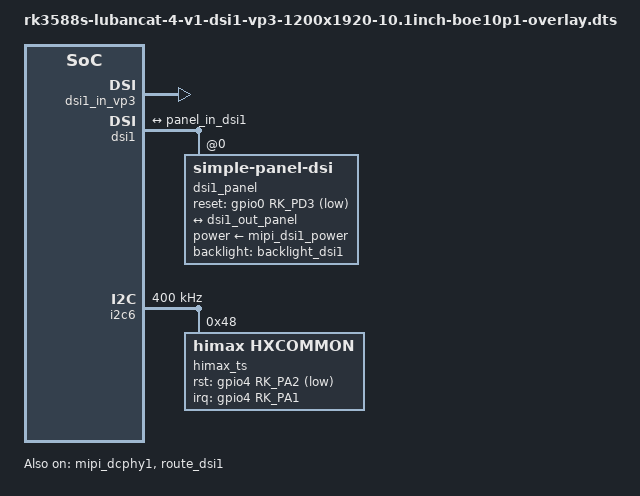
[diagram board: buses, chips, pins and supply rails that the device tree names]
/dts-v1/;
/plugin/;

#include <dt-bindings/gpio/gpio.h>
#include <dt-bindings/pinctrl/rockchip.h>
#include <dt-bindings/display/drm_mipi_dsi.h>
#include <dt-bindings/interrupt-controller/irq.h>

/ {
	fragment@0 {
		target = <&mipi_dcphy1>;

		__overlay__ {
			status = "okay";
		};
	};

	fragment@1 {
		target = <&route_dsi1>;

		__overlay__ {
			status = "okay";
			connect = <&vp3_out_dsi1>;
		};
	};

	fragment@2 {
		target = <&dsi1_in_vp3>;

		__overlay__ {
			status = "okay";
		};
	};

	fragment@3 {
		target = <&dsi1>;

		__overlay__ {
			status = "okay";
			#address-cells = <1>;
			#size-cells = <0>;

			dsi1_panel: panel@0 {
				status = "okay";
				compatible = "simple-panel-dsi";
				reg = <0>;
				backlight = <&backlight_dsi1>;
				power-supply = <&mipi_dsi1_power>;
				reset-gpios = <&gpio0 RK_PD3 GPIO_ACTIVE_LOW>;

				enable-delay-ms = <35>;
				prepare-delay-ms = <6>;
				reset-delay-ms = <10>;
				init-delay-ms = <50>;
				unprepare-delay-ms = <0>;
				disable-delay-ms = <20>;

				size,width = <74>;
				size,height = <133>;

				dsi,flags = <(MIPI_DSI_MODE_VIDEO | MIPI_DSI_MODE_VIDEO_BURST | MIPI_DSI_MODE_LPM | MIPI_DSI_MODE_NO_EOT_PACKET)>;
				dsi,format = <MIPI_DSI_FMT_RGB888>;
				dsi,lanes  = <4>;
				rotation = <90>;

				panel-init-sequence = [
					39 01 04 B9 83 10 2E
					39 01 05 D1 67 0C FF 05
					39 01 12 B1 10 FA AF AF 2B 2B C1 75 39 36 36 36 36 22 21 15 00
					39 01 03 D2 2B 2B
					39 01 11 B2 00 B0 47 80 00 2C 7E 2D 00 00 00 00 15 20 D7 00
					15 01 02 BD 03
					15 01 02 B2 80
					15 01 02 BD 00
					39 01 11 B4 7E 64 7E 64 7E 64 68 50 01 8E 01 58 00 FF 00 FF
					15 01 02 E9 CD
					15 01 02 BB 01
					15 01 02 E9 00
					39 01 04 BF FC 85 80
					39 01 09 BA 70 03 A8 83 F2 00 C0 0D
					39 05 2C D3 00 00 00 00 01 04 00 14 0C 27 27 22 29 29 29 04 04 32 10 27 00 27 32 17 C0 07 C0 32 10 24 00 24 00 00 23 44 7A 68 24 43 7A 68 0F
					39 05 2F E0 00 04 0C 13 19 2A 41 47 4F 4C 68 70 79 8B 8B 95 9F B2 B2 57 5F 69 76 00 04 0C 13 19 2A 41 47 4F 4C 68 70 79 8B 8B 95 9F B2 B2 57 5F 69 76
					39 01 06 CB 00 13 08 02 3E
					15 01 02 BD 01
					39 01 05 B1 01 9B 01 31
					39 01 0B CB 80 36 12 16 C0 28 40 84 02 34
					39 05 0C D3 01 00 7C 00 00 11 10 00 0E 00 01
					15 01 02 BD 02
					39 01 06 CB 00 03 00 01 8F
					39 01 07 B4 4E 00 33 11 33 88
					39 01 04 BF F2 00 02
					15 01 02 BD 00
					39 01 0F C0 23 23 22 11 A2 1F 00 80 00 00 08 00 63 63
					15 01 02 C6 F9
					15 01 02 C7 30
					39 01 07 C8 00 04 04 00 00 82
					39 01 04 D0 07 04 05
					39 05 2D D5 18 18 18 18 2D 2D 21 20 25 24 18 18 39 39 2E 2E 03 02 03 02 01 00 01 00 07 06 07 06 05 04 05 04 18 18 18 18 18 18 18 18 18 18 18 18
					39 05 2D D6 18 18 18 18 18 18 20 21 24 25 2D 2D 39 39 2E 2E 04 05 04 05 06 07 06 07 00 01 00 01 02 03 02 03 18 18 18 18 18 18 18 18 18 18 18 18
					39 01 18 E7 12 13 02 02 4B 4B 0F 0F 19 1C 26 74 28 6B 01 27 00 00 00 00 17 00 68
					15 01 02 BD 01
					39 01 08 E7 02 0C 01 88 0E BC 0F
					15 01 02 BD 02
					39 01 1D E7 FF 01 FD 01 00 00 22 00 00 00 00 00 00 00 00 00 00 00 00 00 00 00 00 00 81 00 02 40
					15 01 02 BD 00
					15 01 02 BD 02
					39 01 0D D8 FF FF FF FF FF F0 FF FF FF FF FF F0
					15 01 02 BD 03
					39 01 19 D8 AA AA AA AA 00 00 AA AA AA AA 00 00 55 55 55 55 00 00 55 55 55 55 00 00
					15 01 02 BD 00
					15 01 02 CC 02
					39 01 03 E1 06 02
					39 01 04 B9 00 00 00
					05 78 01 11
					05 0A 01 29
				];

				panel-exit-sequence = [
					05 0A 01 28
					05 78 01 10
				];

				disp1_timings0: display-timings {
					native-mode = <&dsi1_timing0>;
					dsi1_timing0: timing0 {
						clock-frequency = <153600000>;
						hactive = <1200>;
						vactive = <1920>;
						hsync-len = <8>;
						hback-porch = <28>;
						hfront-porch = <40>;
						vsync-len = <8>;
						vback-porch = <38>;
						vfront-porch = <124>;
						hsync-active = <0>;
						vsync-active = <0>;
						de-active = <0>;
						pixelclk-active = <0>;
					};
				};

				ports {
					#address-cells = <1>;
					#size-cells = <0>;
					port@0 {
						reg = <0>;
						panel_in_dsi1: endpoint {
							remote-endpoint = <&dsi1_out_panel>;
						};
					};
				};
			};

			ports {
				#address-cells = <1>;
				#size-cells = <0>;

				port@1 {
					reg = <1>;
					dsi1_out_panel: endpoint {
						remote-endpoint = <&panel_in_dsi1>;
					};
				};
			};
		};
	};

	fragment@4 {
		target = <&i2c6>;

		__overlay__ {
			status = "okay";
			#address-cells = <1>;
			#size-cells = <0>;
			pinctrl-names = "default";
			pinctrl-0 = <&i2c6m3_xfer>;
			clock-frequency = <400000>;

			himax_ts: himax-ts@48 {
				status = "okay";
				compatible = "himax,hxcommon";
				reg = <0x48>;
				interrupt-parent = <&gpio4>;
				interrupts = <RK_PA1 IRQ_TYPE_LEVEL_LOW>;
				himax,panel-coords = <0 1200 0 1920>;
				himax,display-coords = <0 1200 0 1920>;
				himax,rst-gpio = <&gpio4 RK_PA2 GPIO_ACTIVE_LOW>;
				himax,irq-gpio = <&gpio4 RK_PA1 GPIO_ACTIVE_HIGH>;
				report_type = <1>;
			};
		};
	};
};
